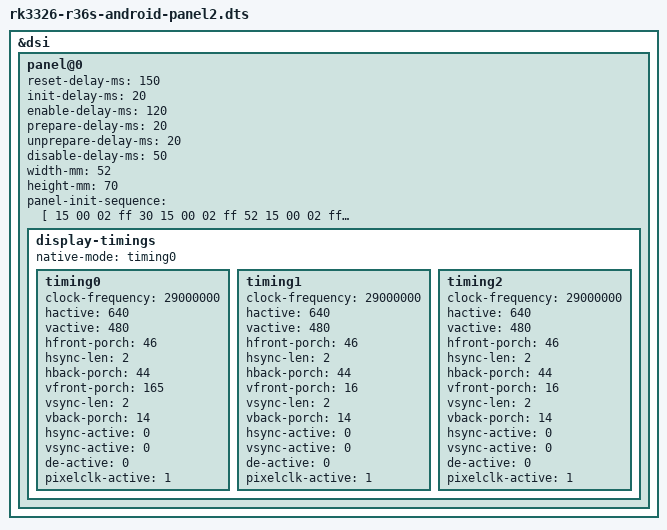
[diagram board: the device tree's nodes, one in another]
// SPDX-License-Identifier: (GPL-2.0+ OR MIT)
/*
 * Copyright (c) 2020 Hardkernel Co., Ltd
 */

/dts-v1/;
#include "rk3326-r36s-android.dtsi"


&dsi {
	panel@0 {
		reset-delay-ms = <150>;
		init-delay-ms = <20>;
		enable-delay-ms = <120>;
		prepare-delay-ms = <20>;
		unprepare-delay-ms = <20>;
		disable-delay-ms = <50>;
		width-mm = <52>;
		height-mm = <70>;
		panel-init-sequence = [
		15 00 02 ff 30 
		15 00 02 ff 52 
		15 00 02 ff 01 
		15 00 02 e3 00 
		15 00 02 40 0a 
		15 00 02 03 40 
		15 00 02 04 00 
		15 00 02 05 03 
		15 00 02 24 12 
		15 00 02 25 1e 
		15 00 02 26 6f 
		15 00 02 27 52 
		15 00 02 28 67 
		15 00 02 29 01 
		15 00 02 2a df 
		15 00 02 37 9c 
		15 00 02 38 a7 
		15 00 02 39 53 
		15 00 02 44 00 
		15 00 02 49 3c 
		15 00 02 59 fe 
		15 00 02 5c 00 
		15 00 02 80 20 
		15 00 02 91 77 
		15 00 02 92 77 
		15 00 02 a0 55 
		15 00 02 a1 50 
		15 00 02 a4 9c 
		15 00 02 a7 02 
		15 00 02 a8 01 
		15 00 02 a9 21 
		15 00 02 aa fc 
		15 00 02 ab 28 
		15 00 02 ac 06 
		15 00 02 ad 06 
		15 00 02 ae 06 
		15 00 02 af 03 
		15 00 02 b0 08 
		15 00 02 b1 26 
		15 00 02 b2 28 
		15 00 02 b3 28 
		15 00 02 b4 33 
		15 00 02 b5 08 
		15 00 02 b6 26 
		15 00 02 b7 08 
		15 00 02 b8 26 
		15 00 02 ff 30 
		15 00 02 ff 52 
		15 00 02 ff 02 
		15 00 02 b0 0b 
		15 00 02 b1 16 
		15 00 02 b2 17 
		15 00 02 b3 2c 
		15 00 02 b4 32 
		15 00 02 b5 3b 
		15 00 02 b6 29 
		15 00 02 b7 40 
		15 00 02 b8 0d 
		15 00 02 b9 05 
		15 00 02 ba 12 
		15 00 02 bb 10 
		15 00 02 bc 12 
		15 00 02 bd 15 
		15 00 02 be 19 
		15 00 02 bf 0e 
		15 00 02 c0 16 
		15 00 02 c1 0a 
		15 00 02 d0 0c 
		15 00 02 d1 17 
		15 00 02 d2 14 
		15 00 02 d3 2e 
		15 00 02 d4 32 
		15 00 02 d5 3c 
		15 00 02 d6 22 
		15 00 02 d7 3d 
		15 00 02 d8 0d 
		15 00 02 d9 07 
		15 00 02 da 13 
		15 00 02 db 13 
		15 00 02 dc 11 
		15 00 02 dd 15 
		15 00 02 de 19 
		15 00 02 df 10 
		15 00 02 e0 17 
		15 00 02 e1 0a 
		15 00 02 ff 30 
		15 00 02 ff 52 
		15 00 02 ff 03 
		15 00 02 00 2a 
		15 00 02 01 2a 
		15 00 02 02 2a 
		15 00 02 03 2a 
		15 00 02 04 61 
		15 00 02 05 80 
		15 00 02 06 c7 
		15 00 02 07 01 
		15 00 02 08 82 
		15 00 02 09 83 
		15 00 02 30 2a 
		15 00 02 31 2a 
		15 00 02 32 2a 
		15 00 02 33 2a 
		15 00 02 34 a1 
		15 00 02 35 c5 
		15 00 02 36 80 
		15 00 02 37 23 
		15 00 02 40 82 
		15 00 02 41 83 
		15 00 02 42 80 
		15 00 02 43 81 
		15 00 02 44 55 
		15 00 02 45 e6 
		15 00 02 46 e5 
		15 00 02 47 55 
		15 00 02 48 e8 
		15 00 02 49 e7 
		15 00 02 50 02 
		15 00 02 51 01 
		15 00 02 52 04 
		15 00 02 53 03 
		15 00 02 54 55 
		15 00 02 55 ea 
		15 00 02 56 e9 
		15 00 02 57 55 
		15 00 02 58 ec 
		15 00 02 59 eb 
		15 00 02 7e 02 
		15 00 02 7f 80 
		15 00 02 e0 5a 
		15 00 02 b1 00 
		15 00 02 b4 0e 
		15 00 02 b5 0f 
		15 00 02 b6 04 
		15 00 02 b7 07 
		15 00 02 b8 06 
		15 00 02 b9 05 
		15 00 02 ba 0f 
		15 00 02 c7 00 
		15 00 02 ca 0e 
		15 00 02 cb 0f 
		15 00 02 cc 04 
		15 00 02 cd 07 
		15 00 02 ce 06 
		15 00 02 cf 05 
		15 00 02 d0 0f 
		15 00 02 81 0f 
		15 00 02 84 0e 
		15 00 02 85 0f 
		15 00 02 86 07 
		15 00 02 87 04 
		15 00 02 88 05 
		15 00 02 89 06 
		15 00 02 8a 00 
		15 00 02 97 0f 
		15 00 02 9a 0e 
		15 00 02 9b 0f 
		15 00 02 9c 07 
		15 00 02 9d 04 
		15 00 02 9e 05 
		15 00 02 9f 06 
		15 00 02 a0 00 
		15 00 02 ff 30 
		15 00 02 ff 52 
		15 00 02 ff 02 
		15 00 02 01 01 
		15 00 02 02 da 
		15 00 02 03 ba 
		15 00 02 04 a8 
		15 00 02 05 9a 
		15 00 02 06 70 
		15 00 02 07 ff 
		15 00 02 08 91 
		15 00 02 09 90 
		15 00 02 0a ff 
		15 00 02 0b 8f 
		15 00 02 0c 60 
		15 00 02 0d 58 
		15 00 02 0e 48 
		15 00 02 0f 38 
		15 00 02 10 2b 
		15 00 02 ff 30 
		15 00 02 ff 52 
		15 00 02 ff 00 
		15 00 02 36 02 
		15 00 02 3a 70 
		05 c8 01 11 
		05 14 01 29
		];

		display-timings {
			native-mode = <&timing0>;

			timing0 {
				clock-frequency = <29000000>;
				hactive = <640>;
				vactive = <480>;
				hfront-porch = <46>;
				hsync-len = <2>;
				hback-porch = <44>;
				vfront-porch = <165>;	/* was 16: 77.4 Hz; 59.94 Hz like Panel 4, same pixel clock */
				vsync-len = <2>;
				vback-porch = <14>;
				hsync-active = <0>;
				vsync-active = <0>;
				de-active = <0>;
				pixelclk-active = <1>;
			};

			timing1 {
				clock-frequency = <29000000>;
				hactive = <640>;
				vactive = <480>;
				hfront-porch = <46>;
				hsync-len = <2>;
				hback-porch = <44>;
				vfront-porch = <16>;
				vsync-len = <2>;
				vback-porch = <14>;
				hsync-active = <0>;
				vsync-active = <0>;
				de-active = <0>;
				pixelclk-active = <1>;
			};

			timing2 {
				clock-frequency = <29000000>;
				hactive = <640>;
				vactive = <480>;
				hfront-porch = <46>;
				hsync-len = <2>;
				hback-porch = <44>;
				vfront-porch = <16>;
				vsync-len = <2>;
				vback-porch = <14>;
				hsync-active = <0>;
				vsync-active = <0>;
				de-active = <0>;
				pixelclk-active = <1>;
			};
		};
	};
};
